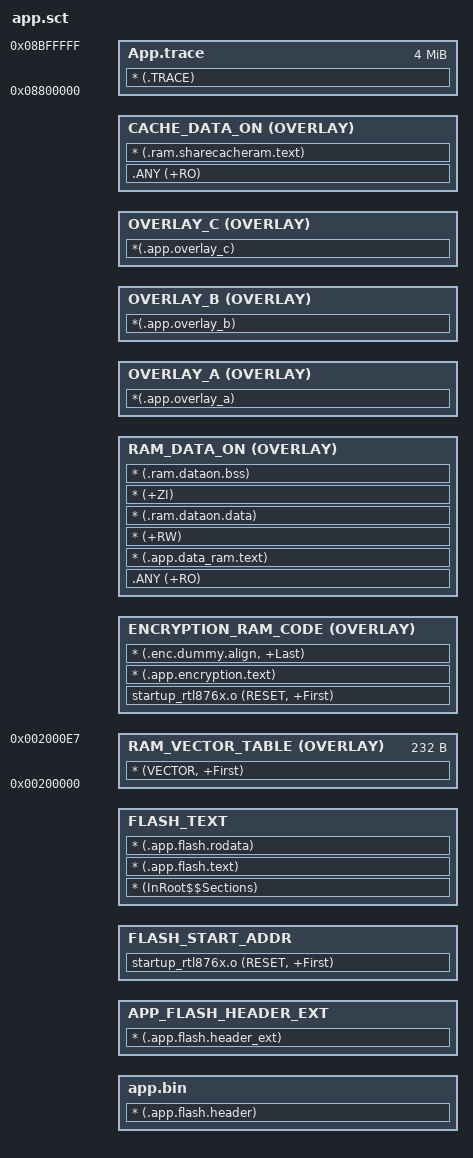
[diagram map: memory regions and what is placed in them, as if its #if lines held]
#! armcc -E
#include "..\mem_config.h"

; *************************************************************
; *** Scatter-Loading Description File generated by uVision ***
; *************************************************************

; APP RAM definitions
#define APP_DATA_ON_ADR                   APP_GLOBAL_ADDR
#define APP_DATA_ON_SIZE                  APP_GLOBAL_SIZE

#define CACHE_DATA_ON_ADR                 SHARE_CACHE_RAM_ADDR
#define CACHE_DATA_ON_SIZE                SHARE_CACHE_RAM_SIZE

#if (APP_BANK == 0)
#define APP_FLASH_ADR                     BANK0_APP_ADDR
#else
#define APP_FLASH_ADR                     BANK1_APP_ADDR
#endif
#define APP_FLASH_SIZE                    BANK0_APP_SIZE

#define APP_TRACE_ADR                     0x08800000
#define APP_TRACE_SIZE                    (4*1024*1024)

#define UPPERSTACK_LIB_IMG_LENGTH      (0x00000104 + 16)

LOAD_FLASH APP_FLASH_ADR APP_FLASH_SIZE
{
    app.bin +0
    {
        * (.app.flash.header)
    }
    APP_FLASH_HEADER_EXT +0
    {
        * (.app.flash.header_ext)
    }

#if (FEATURE_ENCRYPTION == 0)
    FLASH_START_ADDR +0;
    {
        startup_rtl876x.o (RESET, +First)
    }
#endif

    FLASH_TEXT +0
    {
#if FEATURE_RAM_CODE
        * (InRoot$$Sections)
#else
        k_buf_queue.o k_dyn_mem_proc.o k_err.o k_event.o k_idle.o
        k_mm.o k_mm_blk.o k_mm_debug.o k_mutex.o k_obj.o k_pend.o
        k_queue.o k_ringbuf.o k_sem.o k_stats.o k_sys.o
        k_task.o k_task_sem.o k_tick.o k_time.o k_timer.o k_workqueue.o
        osif_AliOS_sdk.o port_c.o port_s.o port_osif.o

        clock.o components.o cpu.o device.o idle.o ipc.o irq.o
        kservice.o mem.o memheap.o mempool.o object.o scheduler.o
        signal.o slab.o thread.o timer.o osif_RTT_sdk.o context_rvds.o cpuport.o

        los_err.o los_event.o los_exc.o los_heap.o los_init.o los_membox.o
        los_memcheck.o los_memory.o los_memstat.o los_misc.o los_mux.o
        los_priqueue.o los_queue.o los_sem.o los_slab.o los_slabmem.o
        los_swtmr.o los_sys.o los_task.o los_tick.o los_tickless.o los_timeslice.o
        los_hw.o los_hw_tick.o los_hwi.o osif_lite_sdk.o port_liteos_c.o port_liteos_s.o

        .ANY (+RO)
#endif
        * (.app.flash.text)
        * (.app.flash.rodata)
    }

    RAM_VECTOR_TABLE 0x00200000 OVERLAY 0xe8 ; 58 ISRs
    {
        * (VECTOR, +First)
    }

#if (FEATURE_ENCRYPTION == 1)
    ENCRYPTION_RAM_CODE APP_DATA_ON_ADR OVERLAY
    {
        startup_rtl876x.o (RESET, +First)
        * (.app.encryption.text)
        * (.enc.dummy.align, +Last)
    }
#endif

#if (FEATURE_ENCRYPTION == 1)
    RAM_DATA_ON +0 OVERLAY (APP_DATA_ON_SIZE) ;real limit is: (APP_DATA_ON_SIZE - ImageLength(ENCRYPTION_RAM_CODE))
#else
    RAM_DATA_ON APP_DATA_ON_ADR OVERLAY (APP_DATA_ON_SIZE)
#endif
    {
#if FEATURE_RAM_CODE
        .ANY (+RO)
#endif
        * (.app.data_ram.text)
        * (+RW)
        * (.ram.dataon.data)
        * (+ZI)
        * (.ram.dataon.bss)
    }

; overlay section begin
    OVERLAY_A ImageLimit(RAM_DATA_ON) OVERLAY
    {
        *(.app.overlay_a)
    }

    OVERLAY_B ImageLimit(RAM_DATA_ON) OVERLAY
    {
        *(.app.overlay_b)
    }
    OVERLAY_C ImageLimit(RAM_DATA_ON) OVERLAY
    {
        *(.app.overlay_c)
    }
#if (FEATURE_ENCRYPTION == 0)
    ScatterAssert((ImageLength(RAM_DATA_ON) + ImageLength(OVERLAY_A)) <= (APP_DATA_ON_SIZE))
    ScatterAssert((ImageLength(RAM_DATA_ON) + ImageLength(OVERLAY_B)) <= (APP_DATA_ON_SIZE))
    ScatterAssert((ImageLength(RAM_DATA_ON) + ImageLength(OVERLAY_C)) <= (APP_DATA_ON_SIZE))
#else
    ScatterAssert((ImageLength(ENCRYPTION_RAM_CODE) + ImageLength(RAM_DATA_ON) + ImageLength(OVERLAY_A)) <= (APP_DATA_ON_SIZE))
    ScatterAssert((ImageLength(ENCRYPTION_RAM_CODE) + ImageLength(RAM_DATA_ON) + ImageLength(OVERLAY_B)) <= (APP_DATA_ON_SIZE))
    ScatterAssert((ImageLength(ENCRYPTION_RAM_CODE) + ImageLength(RAM_DATA_ON) + ImageLength(OVERLAY_C)) <= (APP_DATA_ON_SIZE))
#endif
; overlay section end

    CACHE_DATA_ON CACHE_DATA_ON_ADR OVERLAY CACHE_DATA_ON_SIZE
    {
#if FEATURE_RAM_CODE
        .ANY (+RO)
#endif
        * (.ram.sharecacheram.text)
    }
}

LOAD_APP_TRACE APP_TRACE_ADR APP_TRACE_SIZE
{
    App.trace APP_TRACE_ADR APP_TRACE_SIZE
    {
        * (.TRACE)
    }
}
